VERSION ""

NS_ :

BS_:

BU_: BKU VMU

BO_ 3221225472 VECTOR__INDEPENDENT_SIG_MSG: 0 Vector__XXX
 SG_ bmsUmaxBatteryCell : 0|16@1+ (0.0015,0) [0|98.3025] "V" Vector__XXX
 SG_ bmsUminBatteryCell : 0|16@1+ (0.0015,0) [0|98.3025] "V" Vector__XXX

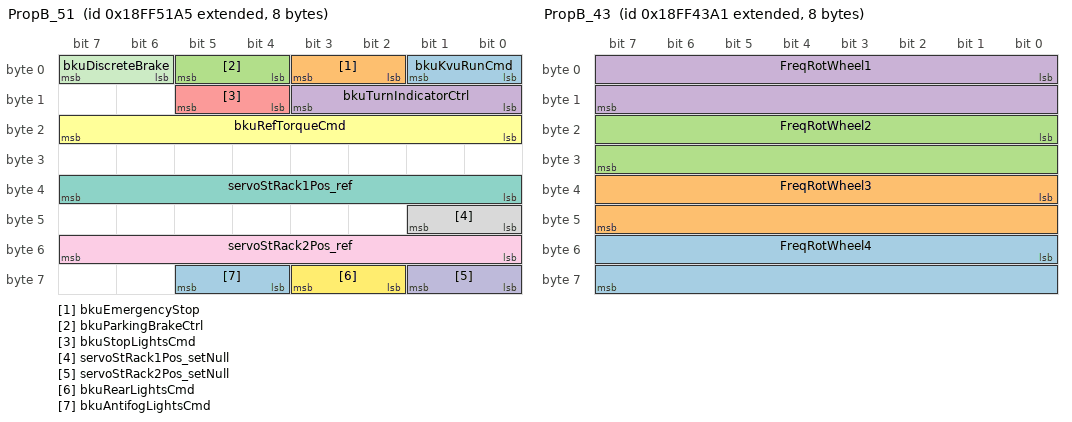
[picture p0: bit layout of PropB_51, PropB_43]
BO_ 2566869413 PropB_51: 8 BKU
 SG_ bkuKvuRunCmd : 0|2@1+ (1,0) [0|3] ""  VMU
 SG_ bkuEmergencyStop : 2|2@1+ (1,0) [0|3] ""  VMU
 SG_ bkuParkingBrakeCtrl : 4|2@1+ (1,0) [0|3] ""  VMU
 SG_ bkuTurnIndicatorCtrl : 8|4@1+ (1,0) [0|15] ""  VMU
 SG_ bkuStopLightsCmd : 12|2@1+ (1,0) [0|3] ""  VMU
 SG_ bkuRefTorqueCmd : 16|8@1+ (1,-100) [-100|155] "%"  VMU
 SG_ servoStRack1Pos_ref : 32|8@1+ (1,-100) [-100|155] "%"  VMU
 SG_ servoStRack1Pos_setNull : 40|2@1+ (1,0) [0|3] ""  VMU
 SG_ servoStRack2Pos_ref : 48|8@1+ (1,-100) [-100|155] "%"  VMU
 SG_ servoStRack2Pos_setNull : 56|2@1+ (1,0) [0|3] ""  VMU
 SG_ bkuDiscreteBrake : 6|2@1+ (1,0) [0|3] ""  VMU
 SG_ bkuRearLightsCmd : 58|2@1+ (1,0) [0|3] ""  VMU
 SG_ bkuAntifogLightsCmd : 60|2@1+ (1,0) [0|3] ""  VMU

BO_ 2566865825 PropB_43: 8 VMU
 SG_ FreqRotWheel4 : 48|16@1+ (0.01,0) [0|655.35] "Гц" Vector__XXX
 SG_ FreqRotWheel3 : 32|16@1+ (0.01,0) [0|655.35] "Гц" Vector__XXX
 SG_ FreqRotWheel2 : 16|16@1+ (0.01,0) [0|655.35] "Гц" Vector__XXX
 SG_ FreqRotWheel1 : 0|16@1+ (0.01,0) [0|655.35] "Гц" Vector__XXX

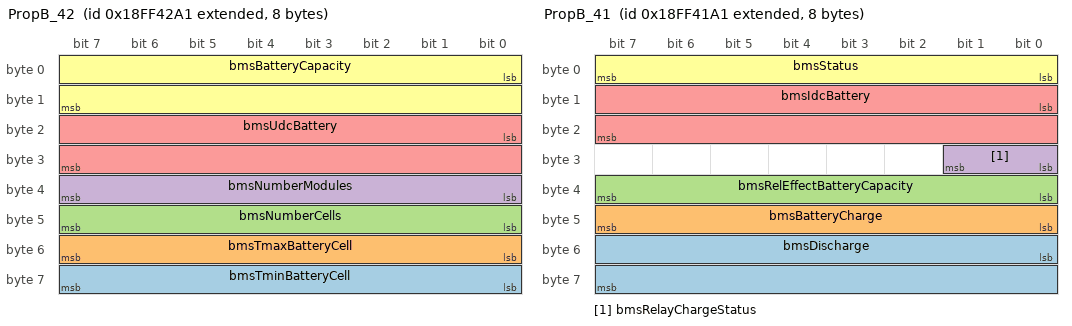
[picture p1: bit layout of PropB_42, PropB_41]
BO_ 2566865569 PropB_42: 8 VMU
 SG_ bmsTminBatteryCell : 56|8@1+ (1,-55) [-55|200] "пїЅC"  BKU
 SG_ bmsTmaxBatteryCell : 48|8@1+ (1,-55) [-55|200] "пїЅC"  BKU
 SG_ bmsNumberCells : 40|8@1+ (1,0) [0|255] ""  BKU
 SG_ bmsNumberModules : 32|8@1+ (1,0) [0|255] ""  BKU
 SG_ bmsUdcBattery : 16|16@1+ (1,0) [0|65535] "V"  BKU
 SG_ bmsBatteryCapacity : 0|16@1+ (1,-512) [-512|65023] "AH"  BKU

BO_ 2566865313 PropB_41: 8 VMU
 SG_ bmsDischarge : 48|16@1+ (1,-512) [-512|65023] "AH"  BKU
 SG_ bmsBatteryCharge : 40|8@1+ (1,0) [0|255] "%"  BKU
 SG_ bmsRelEffectBatteryCapacity : 32|8@1+ (1,0) [0|255] "%"  BKU
 SG_ bmsRelayChargeStatus : 24|2@1+ (1,0) [0|3] ""  BKU
 SG_ bmsIdcBattery : 8|16@1+ (1,-2000) [-2000|63535] "A"  BKU
 SG_ bmsStatus : 0|8@1+ (1,0) [0|255] ""  BKU

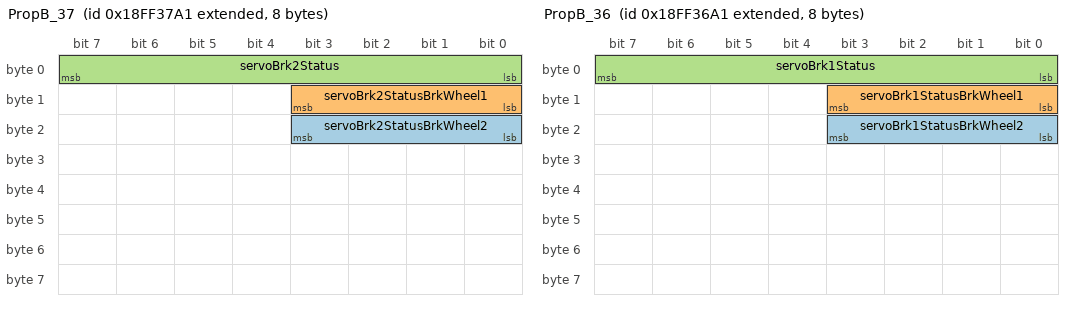
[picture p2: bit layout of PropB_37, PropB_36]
BO_ 2566862753 PropB_37: 8 VMU
 SG_ servoBrk2StatusBrkWheel2 : 16|4@1+ (1,0) [0|15] ""  BKU
 SG_ servoBrk2StatusBrkWheel1 : 8|4@1+ (1,0) [0|15] ""  BKU
 SG_ servoBrk2Status : 0|8@1+ (1,0) [0|255] ""  BKU

BO_ 2566862497 PropB_36: 8 VMU
 SG_ servoBrk1StatusBrkWheel2 : 16|4@1+ (1,0) [0|15] ""  BKU
 SG_ servoBrk1StatusBrkWheel1 : 8|4@1+ (1,0) [0|15] ""  BKU
 SG_ servoBrk1Status : 0|8@1+ (1,0) [0|255] ""  BKU

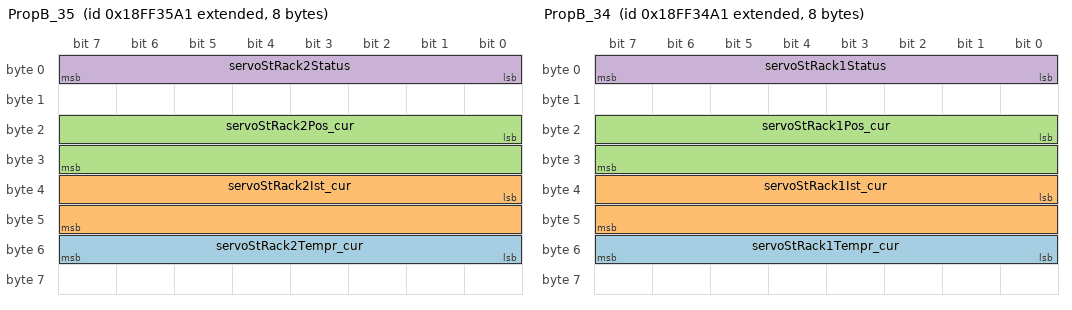
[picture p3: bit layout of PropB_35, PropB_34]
BO_ 2566862241 PropB_35: 8 VMU
 SG_ servoStRack2Tempr_cur : 48|8@1+ (1,-40) [-40|215] "пїЅC"  BKU
 SG_ servoStRack2Ist_cur : 32|16@1+ (1,-30000) [-30000|35535] "mA"  BKU
 SG_ servoStRack2Pos_cur : 16|16@1+ (1,-30000) [-30000|35535] ""  BKU
 SG_ servoStRack2Status : 0|8@1+ (1,0) [0|255] ""  BKU

BO_ 2566861985 PropB_34: 8 VMU
 SG_ servoStRack1Tempr_cur : 48|8@1+ (1,-40) [-40|215] "пїЅC"  BKU
 SG_ servoStRack1Ist_cur : 32|16@1+ (1,-30000) [-30000|35535] "mA"  BKU
 SG_ servoStRack1Pos_cur : 16|16@1+ (1,-30000) [-30000|35535] ""  BKU
 SG_ servoStRack1Status : 0|8@1+ (1,0) [0|255] ""  BKU

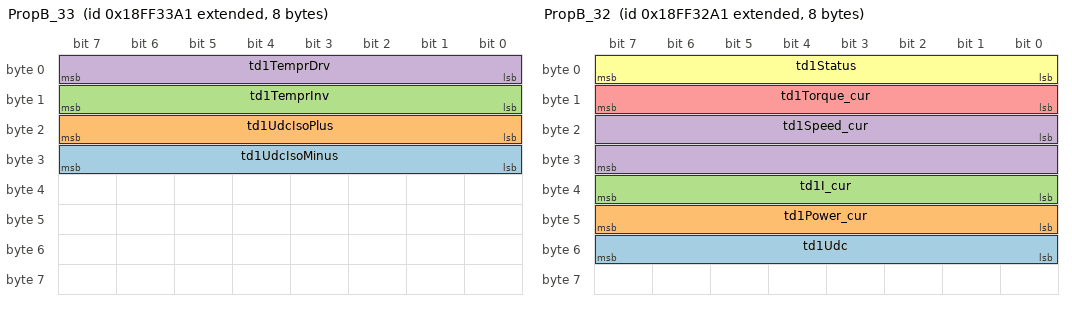
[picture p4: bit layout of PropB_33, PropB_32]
BO_ 2566861729 PropB_33: 8 VMU
 SG_ td1UdcIsoMinus : 24|8@1+ (2,0) [0|510] "V"  BKU
 SG_ td1UdcIsoPlus : 16|8@1+ (2,0) [0|510] "V"  BKU
 SG_ td1TemprInv : 8|8@1+ (1,-40) [-40|215] "пїЅC"  BKU
 SG_ td1TemprDrv : 0|8@1+ (1,-40) [-40|215] "пїЅC"  BKU

BO_ 2566861473 PropB_32: 8 VMU
 SG_ td1Udc : 48|8@1+ (2,0) [0|510] "V"  BKU
 SG_ td1Power_cur : 40|8@1+ (1,-125) [-125|130] "kW"  BKU
 SG_ td1I_cur : 32|8@1+ (3,-375) [-375|390] "A"  BKU
 SG_ td1Speed_cur : 16|16@1+ (0.25,-7500) [-7500|8883.75] "rpm"  BKU
 SG_ td1Torque_cur : 8|8@1+ (1,-100) [-100|155] "%"  BKU
 SG_ td1Status : 0|8@1+ (1,0) [0|255] ""  BKU

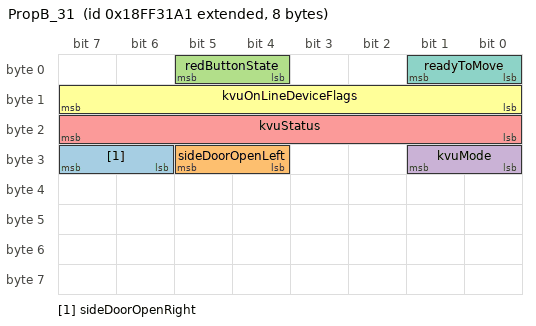
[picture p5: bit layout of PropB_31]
BO_ 2566861217 PropB_31: 8 VMU
 SG_ sideDoorOpenRight : 30|2@1+ (1,0) [0|3] ""  BKU
 SG_ sideDoorOpenLeft : 28|2@1+ (1,0) [0|3] ""  BKU
 SG_ redButtonState : 4|2@1+ (1,0) [0|3] "" Vector__XXX
 SG_ kvuMode : 24|2@1+ (1,0) [0|3] ""  BKU
 SG_ kvuStatus : 16|8@1+ (1,0) [0|255] ""  BKU
 SG_ kvuOnLineDeviceFlags : 8|8@1+ (1,0) [0|255] ""  BKU
 SG_ readyToMove : 0|2@1+ (1,0) [0|3] ""  BKU

CM_ BO_ 3221225472 "This is a message for not used signals, created by Vector CANdb++ DBC OLE DB Provider.";
CM_ SG_ 3221225472 bmsUmaxBatteryCell "пїЅпїЅпїЅпїЅпїЅпїЅпїЅпїЅ пїЅпїЅпїЅпїЅпїЅпїЅпїЅпїЅпїЅпїЅ пїЅпїЅ пїЅпїЅпїЅпїЅпїЅпїЅ";
CM_ SG_ 3221225472 bmsUminBatteryCell "пїЅпїЅпїЅпїЅпїЅпїЅпїЅ пїЅпїЅпїЅпїЅпїЅпїЅпїЅпїЅпїЅпїЅ пїЅпїЅ пїЅпїЅпїЅпїЅпїЅпїЅ";
CM_ SG_ 2566869413 bkuKvuRunCmd "пїЅпїЅпїЅпїЅпїЅпїЅпїЅпїЅпїЅ/пїЅпїЅпїЅпїЅпїЅпїЅпїЅпїЅпїЅпїЅ пїЅпїЅпїЅ";
CM_ SG_ 2566869413 bkuEmergencyStop "пїЅпїЅпїЅпїЅпїЅпїЅпїЅпїЅпїЅ пїЅпїЅпїЅпїЅпїЅпїЅпїЅ";
CM_ SG_ 2566869413 bkuParkingBrakeCtrl "пїЅпїЅпїЅпїЅпїЅпїЅпїЅпїЅпїЅ/пїЅпїЅпїЅпїЅпїЅпїЅпїЅпїЅпїЅпїЅ пїЅпїЅпїЅпїЅпїЅпїЅпїЅпїЅпїЅпїЅпїЅ пїЅпїЅпїЅпїЅпїЅпїЅпїЅ";
CM_ SG_ 2566869413 bkuTurnIndicatorCtrl "пїЅпїЅпїЅпїЅпїЅпїЅпїЅпїЅпїЅпїЅ пїЅпїЅпїЅпїЅпїЅпїЅпїЅпїЅпїЅпїЅпїЅ пїЅпїЅпїЅпїЅпїЅпїЅпїЅпїЅ";
CM_ SG_ 2566869413 bkuStopLightsCmd "пїЅпїЅпїЅпїЅпїЅпїЅпїЅ пїЅпїЅпїЅпїЅпїЅпїЅпїЅпїЅпїЅпїЅ пїЅпїЅпїЅпїЅ-пїЅпїЅпїЅпїЅпїЅпїЅпїЅпїЅпїЅ";
CM_ SG_ 2566869413 bkuRefTorqueCmd "пїЅпїЅпїЅпїЅпїЅпїЅпїЅ пїЅпїЅпїЅпїЅпїЅпїЅпїЅ пїЅпїЅ пїЅпїЅпїЅпїЅпїЅпїЅпїЅ пїЅпїЅпїЅпїЅпїЅпїЅпїЅпїЅпїЅ";
CM_ SG_ 2566869413 servoStRack1Pos_ref "пїЅпїЅпїЅпїЅпїЅпїЅпїЅ пїЅпїЅпїЅпїЅпїЅпїЅпїЅпїЅпїЅ пїЅпїЅпїЅпїЅпїЅпїЅпїЅпїЅпїЅпїЅпїЅпїЅ пїЅпїЅпїЅпїЅ пїЅпїЅпїЅпїЅпїЅпїЅпїЅпїЅ пїЅпїЅпїЅ";
CM_ SG_ 2566869413 servoStRack1Pos_setNull "пїЅпїЅпїЅпїЅпїЅпїЅпїЅ пїЅпїЅпїЅпїЅпїЅпїЅпїЅпїЅ пїЅпїЅпїЅпїЅпїЅпїЅпїЅ пїЅпїЅпїЅпїЅпїЅпїЅпїЅпїЅпїЅ пїЅпїЅ пїЅпїЅпїЅпїЅпїЅ пїЅпїЅпїЅпїЅпїЅпїЅпїЅпїЅпїЅпїЅпїЅпїЅ пїЅпїЅпїЅпїЅ пїЅпїЅпїЅпїЅпїЅпїЅпїЅпїЅ пїЅпїЅпїЅ";
CM_ SG_ 2566869413 servoStRack2Pos_ref "пїЅпїЅпїЅпїЅпїЅпїЅпїЅ пїЅпїЅпїЅпїЅпїЅпїЅпїЅпїЅпїЅ пїЅпїЅпїЅпїЅпїЅпїЅпїЅпїЅпїЅпїЅпїЅпїЅ пїЅпїЅпїЅпїЅ пїЅпїЅпїЅпїЅпїЅпїЅ пїЅпїЅпїЅ";
CM_ SG_ 2566869413 servoStRack2Pos_setNull "пїЅпїЅпїЅпїЅпїЅпїЅпїЅ пїЅпїЅпїЅпїЅпїЅпїЅпїЅпїЅ пїЅпїЅпїЅпїЅпїЅпїЅпїЅ пїЅпїЅпїЅпїЅпїЅпїЅпїЅпїЅпїЅ пїЅпїЅ пїЅпїЅпїЅпїЅпїЅ пїЅпїЅпїЅпїЅпїЅпїЅпїЅпїЅпїЅпїЅпїЅпїЅ пїЅпїЅпїЅпїЅ пїЅпїЅпїЅпїЅпїЅпїЅ пїЅпїЅпїЅ";
CM_ SG_ 2566869413 bkuDiscreteBrake "пїЅпїЅпїЅпїЅпїЅпїЅпїЅ пїЅпїЅ пїЅпїЅпїЅпїЅпїЅпїЅпїЅпїЅпїЅ пїЅпїЅпїЅпїЅпїЅпїЅпїЅпїЅпїЅпїЅпїЅ пїЅпїЅпїЅпїЅпїЅпїЅпїЅ";
CM_ SG_ 2566869413 bkuRearLightsCmd "пїЅпїЅпїЅпїЅпїЅпїЅпїЅ пїЅпїЅпїЅпїЅпїЅпїЅпїЅпїЅпїЅпїЅ пїЅпїЅпїЅпїЅ-пїЅпїЅпїЅпїЅпїЅпїЅпїЅпїЅпїЅ";
CM_ SG_ 2566869413 bkuAntifogLightsCmd "пїЅпїЅпїЅпїЅпїЅпїЅпїЅ пїЅпїЅпїЅпїЅпїЅпїЅпїЅпїЅпїЅпїЅ пїЅпїЅпїЅпїЅ-пїЅпїЅпїЅпїЅпїЅпїЅпїЅпїЅпїЅ";
CM_ SG_ 2566865825 FreqRotWheel4 "Частота вращения колеса 4";
CM_ SG_ 2566865825 FreqRotWheel3 "Частота вращения колеса 3";
CM_ SG_ 2566865825 FreqRotWheel2 "Частота вращения колеса 2";
CM_ SG_ 2566865825 FreqRotWheel1 "Частота вращения колеса 1";
CM_ SG_ 2566865569 bmsTminBatteryCell "пїЅпїЅпїЅпїЅпїЅпїЅпїЅпїЅпїЅпїЅпїЅ пїЅпїЅпїЅпїЅпїЅпїЅпїЅпїЅпїЅпїЅпїЅ";
CM_ SG_ 2566865569 bmsTmaxBatteryCell "пїЅпїЅпїЅпїЅпїЅпїЅпїЅпїЅпїЅпїЅпїЅпїЅ пїЅпїЅпїЅпїЅпїЅпїЅпїЅпїЅпїЅпїЅпїЅ";
CM_ SG_ 2566865569 bmsNumberCells "пїЅпїЅпїЅпїЅпїЅпїЅпїЅпїЅпїЅпїЅ пїЅпїЅпїЅпїЅпїЅ";
CM_ SG_ 2566865569 bmsNumberModules "пїЅпїЅпїЅпїЅпїЅпїЅпїЅпїЅпїЅпїЅ пїЅпїЅпїЅпїЅпїЅпїЅпїЅ";
CM_ SG_ 2566865569 bmsUdcBattery "пїЅпїЅпїЅпїЅпїЅпїЅпїЅпїЅпїЅ пїЅпїЅпїЅпїЅпїЅпїЅпїЅпїЅпїЅпїЅ. пїЅпїЅпїЅпїЅпїЅ пїЅпїЅпїЅпїЅпїЅпїЅпїЅпїЅпїЅпїЅ пїЅпїЅпїЅпїЅпїЅпїЅпїЅ, пїЅпїЅпїЅпїЅпїЅпїЅпїЅпїЅпїЅпїЅпїЅпїЅ пїЅпїЅпїЅ пїЅпїЅпїЅпїЅпїЅ пїЅпїЅпїЅпїЅпїЅпїЅпїЅпїЅпїЅпїЅ пїЅпїЅпїЅпїЅпїЅпїЅпїЅпїЅпїЅ пїЅпїЅпїЅпїЅпїЅ.";
CM_ SG_ 2566865569 bmsBatteryCapacity "пїЅпїЅпїЅпїЅпїЅпїЅпїЅ пїЅпїЅпїЅпїЅпїЅпїЅпїЅ, пїЅпїЅпїЅпїЅпїЅпїЅпїЅпїЅпїЅпїЅ BMS";
CM_ SG_ 2566865313 bmsDischarge "пїЅпїЅпїЅпїЅпїЅпїЅпїЅ пїЅпїЅпїЅпїЅпїЅпїЅпїЅ. пїЅпїЅпїЅпїЅпїЅпїЅпїЅпїЅпїЅпїЅ пїЅпїЅпїЅпїЅпїЅпїЅпїЅ, пїЅпїЅпїЅпїЅпїЅпїЅпїЅпїЅпїЅпїЅ пїЅпїЅ пїЅпїЅпїЅпїЅпїЅпїЅпїЅ (пїЅпїЅпїЅпїЅпїЅпїЅпїЅпїЅпїЅпїЅпїЅпїЅпїЅ пїЅпїЅпїЅпїЅпїЅпїЅпїЅпїЅ), пїЅпїЅпїЅ пїЅпїЅпїЅпїЅпїЅпїЅпїЅпїЅпїЅпїЅ пїЅ пїЅпїЅпїЅпїЅпїЅпїЅпїЅ (пїЅпїЅпїЅпїЅпїЅпїЅпїЅпїЅпїЅпїЅпїЅпїЅпїЅ пїЅпїЅпїЅпїЅпїЅпїЅпїЅпїЅ)";
CM_ SG_ 2566865313 bmsBatteryCharge "пїЅпїЅпїЅпїЅпїЅпїЅпїЅ пїЅпїЅпїЅпїЅпїЅ пїЅпїЅпїЅпїЅпїЅпїЅпїЅ пїЅпїЅпїЅпїЅпїЅпїЅпїЅ";
CM_ SG_ 2566865313 bmsRelEffectBatteryCapacity "пїЅпїЅпїЅпїЅпїЅпїЅпїЅпїЅпїЅпїЅпїЅ пїЅпїЅпїЅпїЅпїЅпїЅпїЅпїЅпїЅпїЅпїЅпїЅпїЅпїЅ пїЅпїЅпїЅпїЅпїЅпїЅпїЅ";
CM_ SG_ 2566865313 bmsRelayChargeStatus "пїЅпїЅпїЅпїЅпїЅпїЅпїЅпїЅпїЅ пїЅпїЅпїЅпїЅ пїЅпїЅпїЅпїЅпїЅпїЅпїЅпїЅпїЅпїЅ пїЅпїЅпїЅпїЅпїЅпїЅ пїЅ пїЅпїЅпїЅпїЅ пїЅпїЅпїЅпїЅпїЅпїЅпїЅ";
CM_ SG_ 2566865313 bmsIdcBattery "пїЅпїЅпїЅпїЅпїЅпїЅпїЅпїЅпїЅпїЅ пїЅпїЅпїЅпїЅпїЅпїЅпїЅ";
CM_ SG_ 2566865313 bmsStatus "пїЅпїЅпїЅпїЅпїЅпїЅпїЅ пїЅпїЅпїЅпїЅпїЅпїЅ пїЅпїЅпїЅпїЅпїЅпїЅпїЅпїЅпїЅпїЅпїЅ пїЅпїЅпїЅпїЅпїЅпїЅпїЅпїЅпїЅпїЅ пїЅпїЅпїЅпїЅпїЅпїЅпїЅ пїЅпїЅпїЅпїЅпїЅпїЅпїЅпїЅпїЅпїЅпїЅпїЅпїЅпїЅ пїЅпїЅпїЅпїЅпїЅпїЅпїЅ";
CM_ SG_ 2566862753 servoBrk2StatusBrkWheel2 "пїЅпїЅпїЅпїЅпїЅпїЅпїЅпїЅпїЅ пїЅпїЅпїЅпїЅпїЅпїЅпїЅпїЅпїЅпїЅпїЅпїЅпїЅпїЅ пїЅпїЅпїЅпїЅпїЅпїЅпїЅпїЅпїЅпїЅпїЅ пїЅпїЅпїЅпїЅпїЅпїЅпїЅ (пїЅпїЅпїЅпїЅпїЅпїЅпїЅ/пїЅпїЅпїЅпїЅпїЅпїЅпїЅ) пїЅпїЅпїЅпїЅпїЅпїЅ 2 пїЅпїЅпїЅпїЅпїЅпїЅ пїЅпїЅпїЅ";
CM_ SG_ 2566862753 servoBrk2StatusBrkWheel1 "пїЅпїЅпїЅпїЅпїЅпїЅпїЅпїЅпїЅ пїЅпїЅпїЅпїЅпїЅпїЅпїЅпїЅпїЅпїЅпїЅпїЅпїЅпїЅ пїЅпїЅпїЅпїЅпїЅпїЅпїЅпїЅпїЅпїЅпїЅ пїЅпїЅпїЅпїЅпїЅпїЅпїЅ (пїЅпїЅпїЅпїЅпїЅпїЅпїЅ/пїЅпїЅпїЅпїЅпїЅпїЅпїЅ) пїЅпїЅпїЅпїЅпїЅпїЅ 1 пїЅпїЅпїЅпїЅпїЅпїЅ пїЅпїЅпїЅ";
CM_ SG_ 2566862753 servoBrk2Status "пїЅпїЅпїЅпїЅпїЅпїЅпїЅ пїЅпїЅпїЅпїЅпїЅпїЅ пїЅпїЅпїЅпїЅпїЅ пїЅпїЅпїЅпїЅпїЅпїЅпїЅпїЅпїЅпїЅ пїЅпїЅпїЅпїЅпїЅпїЅпїЅпїЅпїЅпїЅпїЅпїЅпїЅпїЅ пїЅпїЅпїЅпїЅпїЅпїЅпїЅпїЅпїЅпїЅпїЅ пїЅпїЅпїЅпїЅпїЅпїЅпїЅ пїЅпїЅпїЅпїЅпїЅпїЅ пїЅпїЅпїЅ";
CM_ SG_ 2566862497 servoBrk1StatusBrkWheel2 "пїЅпїЅпїЅпїЅпїЅпїЅпїЅпїЅпїЅ пїЅпїЅпїЅпїЅпїЅпїЅпїЅпїЅпїЅпїЅпїЅпїЅпїЅпїЅ пїЅпїЅпїЅпїЅпїЅпїЅпїЅпїЅпїЅпїЅпїЅ пїЅпїЅпїЅпїЅпїЅпїЅпїЅ (пїЅпїЅпїЅпїЅпїЅпїЅпїЅ/пїЅпїЅпїЅпїЅпїЅпїЅпїЅ) пїЅпїЅпїЅпїЅпїЅпїЅ 2 пїЅпїЅпїЅпїЅпїЅпїЅпїЅпїЅ пїЅпїЅпїЅ";
CM_ SG_ 2566862497 servoBrk1StatusBrkWheel1 "пїЅпїЅпїЅпїЅпїЅпїЅпїЅпїЅпїЅ пїЅпїЅпїЅпїЅпїЅпїЅпїЅпїЅпїЅпїЅпїЅпїЅпїЅпїЅ пїЅпїЅпїЅпїЅпїЅпїЅпїЅпїЅпїЅпїЅпїЅ пїЅпїЅпїЅпїЅпїЅпїЅпїЅ (пїЅпїЅпїЅпїЅпїЅпїЅпїЅ/пїЅпїЅпїЅпїЅпїЅпїЅпїЅ) пїЅпїЅпїЅпїЅпїЅпїЅ 1 пїЅпїЅпїЅпїЅпїЅпїЅпїЅпїЅ пїЅпїЅпїЅ";
CM_ SG_ 2566862497 servoBrk1Status "пїЅпїЅпїЅпїЅпїЅпїЅпїЅ пїЅпїЅпїЅпїЅпїЅпїЅ пїЅпїЅпїЅпїЅпїЅ пїЅпїЅпїЅпїЅпїЅпїЅпїЅпїЅпїЅпїЅ пїЅпїЅпїЅпїЅпїЅпїЅпїЅпїЅпїЅпїЅпїЅпїЅпїЅпїЅ пїЅпїЅпїЅпїЅпїЅпїЅпїЅпїЅпїЅпїЅпїЅ пїЅпїЅпїЅпїЅпїЅпїЅпїЅ пїЅпїЅпїЅпїЅпїЅпїЅпїЅпїЅ пїЅпїЅпїЅ";
CM_ SG_ 2566862241 servoStRack2Tempr_cur "пїЅпїЅпїЅпїЅпїЅпїЅпїЅпїЅпїЅпїЅпїЅ пїЅпїЅпїЅпїЅпїЅ пїЅпїЅпїЅпїЅпїЅпїЅпїЅпїЅпїЅпїЅ пїЅпїЅпїЅпїЅпїЅпїЅпїЅпїЅпїЅпїЅпїЅпїЅпїЅпїЅ пїЅпїЅпїЅпїЅпїЅпїЅпїЅ пїЅпїЅпїЅпїЅпїЅ пїЅпїЅпїЅпїЅпїЅпїЅ пїЅпїЅпїЅ";
CM_ SG_ 2566862241 servoStRack2Ist_cur "пїЅпїЅпїЅпїЅпїЅпїЅпїЅ пїЅпїЅпїЅ пїЅпїЅпїЅпїЅпїЅпїЅпїЅ пїЅпїЅпїЅпїЅпїЅпїЅпїЅпїЅпїЅпїЅпїЅпїЅпїЅпїЅ пїЅпїЅпїЅпїЅпїЅпїЅпїЅ пїЅпїЅпїЅпїЅпїЅпїЅпїЅпїЅпїЅпїЅпїЅ пїЅпїЅпїЅ";
CM_ SG_ 2566862241 servoStRack2Pos_cur "пїЅпїЅпїЅпїЅпїЅпїЅпїЅ пїЅпїЅпїЅпїЅпїЅпїЅпїЅпїЅпїЅ пїЅпїЅпїЅпїЅпїЅпїЅпїЅпїЅпїЅпїЅпїЅпїЅпїЅпїЅ пїЅпїЅпїЅпїЅпїЅпїЅпїЅ пїЅпїЅпїЅпїЅпїЅпїЅпїЅпїЅпїЅпїЅпїЅ пїЅпїЅпїЅ";
CM_ SG_ 2566862241 servoStRack2Status "пїЅпїЅпїЅпїЅпїЅпїЅпїЅ пїЅпїЅпїЅпїЅпїЅпїЅ пїЅпїЅпїЅпїЅпїЅ пїЅпїЅпїЅпїЅпїЅпїЅпїЅпїЅпїЅпїЅ пїЅпїЅпїЅпїЅпїЅпїЅпїЅпїЅпїЅпїЅпїЅпїЅпїЅпїЅ пїЅпїЅпїЅпїЅпїЅпїЅпїЅ пїЅпїЅпїЅпїЅпїЅ пїЅпїЅпїЅпїЅпїЅпїЅ пїЅпїЅпїЅ";
CM_ SG_ 2566861985 servoStRack1Tempr_cur "пїЅпїЅпїЅпїЅпїЅпїЅпїЅпїЅпїЅпїЅпїЅ пїЅпїЅпїЅпїЅпїЅпїЅпїЅпїЅпїЅпїЅпїЅпїЅпїЅпїЅпїЅ пїЅпїЅпїЅпїЅпїЅпїЅпїЅпїЅпїЅпїЅпїЅпїЅпїЅпїЅ пїЅпїЅпїЅпїЅпїЅпїЅпїЅ пїЅпїЅпїЅпїЅпїЅпїЅпїЅпїЅпїЅпїЅпїЅпїЅпїЅ пїЅпїЅпїЅ";
CM_ SG_ 2566861985 servoStRack1Ist_cur "пїЅпїЅпїЅпїЅпїЅпїЅпїЅ пїЅпїЅпїЅ пїЅпїЅпїЅпїЅпїЅпїЅпїЅ пїЅпїЅпїЅпїЅпїЅпїЅпїЅпїЅпїЅпїЅпїЅпїЅпїЅпїЅ пїЅпїЅпїЅпїЅпїЅпїЅпїЅ пїЅпїЅпїЅпїЅпїЅпїЅпїЅпїЅпїЅпїЅпїЅпїЅпїЅ пїЅпїЅпїЅ";
CM_ SG_ 2566861985 servoStRack1Pos_cur "пїЅпїЅпїЅпїЅпїЅпїЅпїЅ пїЅпїЅпїЅпїЅпїЅпїЅпїЅпїЅпїЅ пїЅпїЅпїЅпїЅпїЅпїЅпїЅпїЅпїЅпїЅпїЅпїЅпїЅпїЅ пїЅпїЅпїЅпїЅпїЅпїЅпїЅ пїЅпїЅпїЅпїЅпїЅпїЅпїЅпїЅпїЅпїЅпїЅпїЅпїЅ пїЅпїЅпїЅ";
CM_ SG_ 2566861985 servoStRack1Status "пїЅпїЅпїЅпїЅпїЅпїЅпїЅ пїЅпїЅпїЅпїЅпїЅпїЅ пїЅпїЅпїЅпїЅпїЅ пїЅпїЅпїЅпїЅпїЅпїЅпїЅпїЅпїЅпїЅ пїЅпїЅпїЅпїЅпїЅпїЅпїЅпїЅпїЅпїЅпїЅпїЅпїЅпїЅ пїЅпїЅпїЅпїЅпїЅпїЅпїЅ пїЅпїЅпїЅпїЅпїЅ пїЅпїЅпїЅпїЅпїЅпїЅпїЅпїЅ пїЅпїЅпїЅ";
CM_ SG_ 2566861729 td1UdcIsoMinus "пїЅпїЅпїЅпїЅпїЅпїЅпїЅпїЅпїЅпїЅ пїЅпїЅпїЅпїЅпїЅпїЅпїЅпїЅпїЅ пїЅпїЅпїЅпїЅ пїЅпїЅпїЅ пїЅпїЅпїЅпїЅпїЅпїЅпїЅпїЅпїЅпїЅпїЅпїЅ пїЅпїЅпїЅпїЅпїЅпїЅпїЅ";
CM_ SG_ 2566861729 td1UdcIsoPlus "пїЅпїЅпїЅпїЅпїЅпїЅпїЅпїЅпїЅпїЅ пїЅпїЅпїЅпїЅпїЅпїЅпїЅпїЅ пїЅпїЅпїЅпїЅ пїЅпїЅпїЅ пїЅпїЅпїЅпїЅпїЅпїЅпїЅпїЅпїЅпїЅпїЅпїЅ пїЅпїЅпїЅпїЅпїЅпїЅпїЅ";
CM_ SG_ 2566861729 td1TemprInv "пїЅпїЅпїЅпїЅпїЅпїЅпїЅпїЅпїЅпїЅпїЅ пїЅпїЅпїЅпїЅпїЅпїЅпїЅпїЅ пїЅпїЅпїЅпїЅпїЅпїЅпїЅпїЅпїЅпїЅпїЅпїЅпїЅпїЅпїЅ пїЅпїЅпїЅпїЅпїЅпїЅпїЅпїЅ пїЅпїЅпїЅпїЅпїЅпїЅпїЅпїЅпїЅ";
CM_ SG_ 2566861729 td1TemprDrv "пїЅпїЅпїЅпїЅпїЅпїЅпїЅпїЅпїЅпїЅпїЅ пїЅпїЅпїЅпїЅпїЅпїЅпїЅпїЅ пїЅпїЅпїЅпїЅпїЅпїЅпїЅпїЅпїЅ";
CM_ SG_ 2566861473 td1Udc "пїЅпїЅпїЅпїЅпїЅпїЅпїЅпїЅпїЅпїЅ пїЅпїЅпїЅпїЅпїЅ пїЅпїЅпїЅпїЅпїЅпїЅпїЅпїЅпїЅпїЅпїЅ пїЅпїЅпїЅпїЅ пїЅпїЅпїЅпїЅпїЅ";
CM_ SG_ 2566861473 td1Power_cur "пїЅпїЅпїЅпїЅпїЅпїЅпїЅпїЅ пїЅпїЅпїЅпїЅпїЅпїЅпїЅпїЅ пїЅпїЅпїЅпїЅпїЅпїЅпїЅпїЅпїЅ";
CM_ SG_ 2566861473 td1I_cur "пїЅпїЅпїЅпїЅпїЅпїЅпїЅпїЅпїЅпїЅпїЅпїЅпїЅпїЅпїЅ";
CM_ SG_ 2566861473 td1Speed_cur "пїЅпїЅпїЅпїЅпїЅпїЅпїЅ пїЅпїЅпїЅпїЅпїЅпїЅпїЅпїЅ пїЅпїЅпїЅпїЅпїЅпїЅпїЅпїЅ пїЅпїЅпїЅпїЅпїЅпїЅпїЅпїЅпїЅ";
CM_ SG_ 2566861473 td1Torque_cur "пїЅпїЅпїЅпїЅпїЅпїЅпїЅ пїЅпїЅпїЅпїЅпїЅпїЅпїЅ пїЅпїЅпїЅпїЅпїЅпїЅпїЅпїЅпїЅпїЅпїЅпїЅ пїЅпїЅпїЅпїЅпїЅпїЅпїЅ";
CM_ SG_ 2566861473 td1Status "пїЅпїЅпїЅпїЅпїЅпїЅпїЅ пїЅпїЅпїЅпїЅпїЅпїЅ пїЅпїЅпїЅпїЅпїЅпїЅпїЅпїЅпїЅпїЅпїЅпїЅпїЅпїЅпїЅ пїЅпїЅпїЅпїЅпїЅпїЅпїЅпїЅ пїЅпїЅпїЅпїЅпїЅпїЅпїЅпїЅ пїЅпїЅпїЅпїЅпїЅпїЅпїЅпїЅпїЅпїЅпїЅпїЅпїЅпїЅпїЅпїЅ (пїЅпїЅ пїЅпїЅпїЅ)";
CM_ SG_ 2566861217 sideDoorOpenRight "Current state of the Emergency buttton.
0 = not pressed.
1 = pressed.";
CM_ SG_ 2566861217 sideDoorOpenLeft "Current state of the Emergency buttton.
0 = not pressed.
1 = pressed.";
CM_ SG_ 2566861217 redButtonState "Current state of the Emergency buttton.
0 = not pressed.
1 = pressed.";
CM_ SG_ 2566861217 kvuMode "пїЅпїЅпїЅпїЅпїЅ пїЅпїЅпїЅпїЅпїЅпїЅ пїЅпїЅпїЅ";
CM_ SG_ 2566861217 kvuStatus "пїЅпїЅпїЅпїЅпїЅпїЅпїЅ пїЅпїЅпїЅпїЅпїЅпїЅ пїЅпїЅпїЅ";
CM_ SG_ 2566861217 kvuOnLineDeviceFlags "пїЅпїЅпїЅпїЅпїЅ пїЅпїЅпїЅпїЅпїЅпїЅпїЅ пїЅпїЅпїЅпїЅпїЅпїЅпїЅпїЅпїЅ пїЅ пїЅпїЅпїЅпїЅ";
CM_ SG_ 2566861217 readyToMove "пїЅпїЅпїЅпїЅпїЅпїЅ пїЅпїЅпїЅпїЅпїЅпїЅпїЅпїЅпїЅпїЅ пїЅпїЅпїЅпїЅ пїЅ пїЅпїЅпїЅпїЅпїЅпїЅпїЅпїЅ";
BA_DEF_ SG_  "SigType" ENUM  "Default","Range","RangeSigned","ASCII","Discrete","Control","ReferencePGN","DTC","StringDelimiter","StringLength","StringLengthControl","MessageCounter","MessageChecksum";
BA_DEF_ SG_  "GenSigEVName" STRING ;
BA_DEF_ SG_  "GenSigILSupport" ENUM  "No","Yes";
BA_DEF_ SG_  "GenSigSendType" ENUM  "Cyclic","OnWrite","OnWriteWithRepetition","OnChange","OnChangeWithRepetition","IfActive","IfActiveWithRepetition","NoSigSendType";
BA_DEF_ SG_  "GenSigStartValue" INT 0 2147483647;
BA_DEF_ BO_  "GenMsgILSupport" ENUM  "No","Yes";
BA_DEF_ BU_  "NmStationAddress" INT 0 255;
BA_DEF_ BO_  "GenMsgSendType" ENUM  "cyclic","NotUsed","IfActive","NotUsed","NotUsed","NotUsed","NotUsed","NotUsed","noMsgSendType";
BA_DEF_ BO_  "GenMsgRequestable" INT 0 1;
BA_DEF_  "DBName" STRING ;
BA_DEF_  "BusType" STRING ;
BA_DEF_  "ProtocolType" STRING ;
BA_DEF_ BO_  "VFrameFormat" ENUM  "StandardCAN","ExtendedCAN","reserved","J1939PG";
BA_DEF_DEF_  "SigType" "Default";
BA_DEF_DEF_  "GenSigEVName" "Env@Nodename_@Signame";
BA_DEF_DEF_  "GenSigILSupport" "Yes";
BA_DEF_DEF_  "GenSigSendType" "NoSigSendType";
BA_DEF_DEF_  "GenSigStartValue" 0;
BA_DEF_DEF_  "GenMsgILSupport" "Yes";
BA_DEF_DEF_  "NmStationAddress" 254;
BA_DEF_DEF_  "GenMsgSendType" "noMsgSendType";
BA_DEF_DEF_  "GenMsgRequestable" 1;
BA_DEF_DEF_  "DBName" "";
BA_DEF_DEF_  "BusType" "CAN";
BA_DEF_DEF_  "ProtocolType" "J1939";
BA_DEF_DEF_  "VFrameFormat" "J1939PG";
BA_ "DBName" "N1_CAN2";
BA_ "NmStationAddress" BU_ BKU 165;
BA_ "NmStationAddress" BU_ VMU 161;
BA_ "GenSigStartValue" SG_ 2566869413 bkuRefTorqueCmd 100;
BA_ "GenSigStartValue" SG_ 2566869413 servoStRack1Pos_ref 100;
BA_ "GenSigStartValue" SG_ 2566869413 servoStRack2Pos_ref 100;
BA_ "GenSigStartValue" SG_ 2566865569 bmsTminBatteryCell 55;
BA_ "GenSigStartValue" SG_ 2566865569 bmsTmaxBatteryCell 55;
BA_ "GenSigStartValue" SG_ 2566865569 bmsBatteryCapacity 512;
BA_ "GenSigStartValue" SG_ 2566865313 bmsDischarge 512;
BA_ "GenSigStartValue" SG_ 2566865313 bmsIdcBattery 2000;
BA_ "GenSigStartValue" SG_ 2566862241 servoStRack2Tempr_cur 40;
BA_ "GenSigStartValue" SG_ 2566862241 servoStRack2Ist_cur 30000;
BA_ "GenSigStartValue" SG_ 2566862241 servoStRack2Pos_cur 30000;
BA_ "GenSigStartValue" SG_ 2566861985 servoStRack1Tempr_cur 40;
BA_ "GenSigStartValue" SG_ 2566861985 servoStRack1Ist_cur 30000;
BA_ "GenSigStartValue" SG_ 2566861985 servoStRack1Pos_cur 30000;
BA_ "GenSigStartValue" SG_ 2566861729 td1TemprInv 40;
BA_ "GenSigStartValue" SG_ 2566861729 td1TemprDrv 40;
BA_ "GenSigStartValue" SG_ 2566861473 td1Power_cur 125;
BA_ "GenSigStartValue" SG_ 2566861473 td1I_cur 125;
BA_ "GenSigStartValue" SG_ 2566861473 td1Speed_cur 30000;
BA_ "GenSigStartValue" SG_ 2566861473 td1Torque_cur 100;
